# NUC122_v1 register map
File version: 1.0
Registers are 32-bit, read-write, reset 0x0 unless marked. A register's access mark holds for its fields unless they carry their own. Offsets are from the block's base; [hi:lo] are bit positions; {n}, {i} and the like mark numbered series.

## GCR — GCR Register Map
Base 0x50000000
0x00 PDID ro reset 0x140018 — Part Device Identification Number Register
  [31:0] PDID — Part Device Identification Number. This register reflects device part number code. S/W can read this register to identify which device is used.
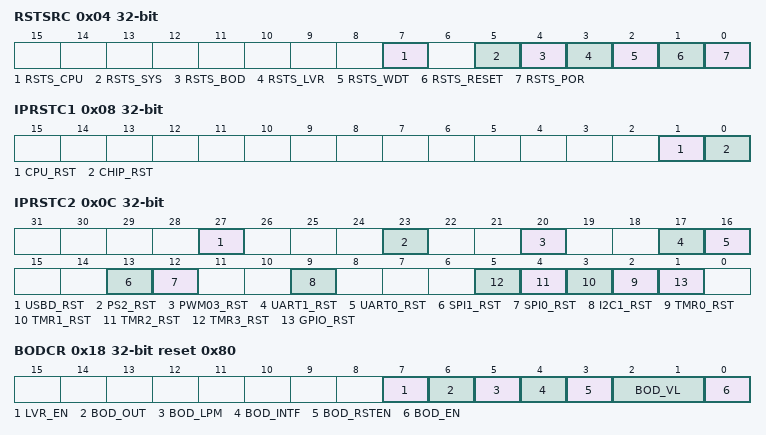
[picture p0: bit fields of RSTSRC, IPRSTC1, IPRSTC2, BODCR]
0x04 RSTSRC (reset mask 0xFFFFFF00) — System Reset Source Register
  [7] RSTS_CPU — The RSTS_CPU flag is set by hardware if software writes CPU_RST (IPRSTC1[1]) 1 to reset Cortex-M0 CPU kernel and Flash memory controller (FMC). Software can write 1 to clear this bit to zero.
    0=No reset from CPU; 1=The Cortex-M0 CPU kernel and FMC are reset by software setting CPU_RST to 1
  [5] RSTS_SYS — The RSTS_SYS flag is set by the "reset signal" from the Cortex-M0 kernel to indicate the previous reset source. Software can write 1 to clear this bit to zero.
    0=No reset from Cortex-M0; 1=The Cortex-M0 had issued the reset signal to reset the system by software writing 1 to bit SYSRESETREQ(AIRCR[2], Application Interrupt and Reset Control Register, address = 0xE000ED0C) in system control registers of Cortex-M0 kernel
  [4] RSTS_BOD — The RSTS_BOD flag is set by the "reset signal" from the Brownout Detector to indicate the previous reset source. Software can write 1 to clear this bit to zero.
    0=No reset from BOD; 1=The BOD had issued the reset signal to reset the system
  [3] RSTS_LVR — The RSTS_LVR flag is set by the "reset signal" from the Low-Voltage-Reset controller to indicate the previous reset source. Software can write 1 to clear this bit to zero.
    0=No reset from LVR; 1=The LVR controller had issued the reset signal to reset the system
  [2] RSTS_WDT — The RSTS_WDT flag is set by the "reset signal" from the Watchdog Timer to indicate the previous reset source. Software can write 1 to clear this bit to zero.
    0=No reset from Watchdog Timer; 1=The Watchdog Timer had issued the reset signal to reset the system
  [1] RSTS_RESET — The RSTS_RESET flag is set by the "reset signal" from the /RESET pin to indicate the previous reset source. Software can write 1 to clear this bit to zero.
    0=No reset from /RESET pin; 1=The Pin /RESET had issued the reset signal to reset the system
  [0] RSTS_POR — The RSTS_POR flag is set by the "reset signal" from the Power-On Reset (POR) controller or bit CHIP_RST (IPRSTC1[0]) to indicate the previous reset source. Software can write 1 to clear this bit to zero.
    0=No reset from POR or CHIP_RST; 1=The Power-On Reset (POR) or CHIP_RST had issued the reset signal to reset the system
0x08 IPRSTC1 — Peripheral Reset Control Register 1
  [1] CPU_RST — CPU Kernel One Shot Reset (write-protection bit). Setting this bit will only reset the CPU kernel and Flash Memory Controller(FMC), and this bit will automatically return to 0 after the 2 clock cycles. This bit is the protected bit, It means programming this bit needs to write "59h", "16h", "88h" to address 0x5000_0100 to disable register protection. Reference the register REGWRPROT at address GCR_BA+0x100
    0=CPU normal operation; 1=CPU one shot reset
  [0] CHIP_RST — CHIP One Shot Reset (write-protection bit). Setting this bit will reset the whole chip, including CPU kernel and all peripherals, and this bit will automatically return to 0 after the 2 clock cycles. The CHIP_RST is same as the POR reset, all the chip controllers is reset and the chip setting from flash are also reload. About the difference between CHIP_RST and SYSRESETREQ, please refer to section 5.2.2. This bit is the protected bit. It means programming this bit needs to write "59h", "16h", "88h" to address 0x5000_0100 to disable register protection. Reference the register REGWRPROT at address GCR_BA+0x100
    0=CHIP normal operation; 1=CHIP one shot reset
0x0C IPRSTC2 — Peripheral Reset Control Register 2
  [27] USBD_RST — USB Device Controller Reset
    0=USB device controller normal operation; 1=USB device controller reset
  [23] PS2_RST — PS/2 Controller Reset
    0=PS/2 controller normal operation; 1=PS/2 controller reset
  [20] PWM03_RST — PWM03 Controller Reset
    0=PWM03 controller normal operation; 1=PWM03 controller reset
  [17] UART1_RST — UART1 Controller Reset
    0=UART1 controller normal operation; 1=UART1 controller reset
  [16] UART0_RST — UART0 Controller Reset
    0=UART0 controller normal operation; 1=UART0 controller reset
  [13] SPI1_RST — SPI1 Controller Reset
    0=SPI1 controller normal operation; 1=SPI1 controller reset
  [12] SPI0_RST — SPI0 Controller Reset
    0=SPI0 controller normal operation; 1=SPI0 controller reset
  [9] I2C1_RST — I2C1 Controller Reset
    0=I2C1 controller normal operation; 1=I2C1 controller reset
  [n+2] TMR{n}_RST (n=0..3) — Timer{n} Controller Reset
    0=Timer{n} controller normal operation; 1=Timer{n} controller reset
  [1] GPIO_RST — GPIO Controller Reset
    0=GPIO controller normal operation; 1=GPIO controller reset
0x18 BODCR reset 0x80 (reset mask 0xFFFFFFF0) — Brownout Detector Control Register
  [7] LVR_EN — Low Voltage Reset Enable (write-protection bit). The LVR function reset the chip when the input power voltage is lower than LVR circuit setting. LVR function is enabled in default. This bit is the protected bit. It means programming this needs to write "59h", "16h", "88h" to address 0x5000_0100 to disable register protection. Reference the register REGWRPROT at address GCR_BA+0x100
    0=Disabled Low Voltage Reset function; 1=Enabled Low Voltage Reset function - After enabling the bit, the LVR function will be active with 100uS delay for LVR output stable. (default)
  [6] BOD_OUT — Brownout Detector Output Status
    0=Brownout Detector output status is 0. It means the detected voltage is higher than BOD_VL setting or BOD_EN is 0; 1=Brownout Detector output status is 1. It means the detected voltage is lower than BOD_VL setting. If the BOD_EN is 0, BOD function disabled , this bit always responds 0
  [5] BOD_LPM — Brownout Detector Low Power Mode (write-protection bit). The BOD consumes about 100 uA in normal mode, the low power mode can reduce the current to about 1/10 but slow the BOD response. This bit is the protected bit. It means programming this needs to write "59h", "16h", "88h" to address 0x5000_0100 to disable register protection. Reference the register REGWRPROT at address GCR_BA+0x100.
    0=BOD operate in normal mode (default); 1=Enable the BOD low power mode
  [4] BOD_INTF — Brownout Detector Interrupt Flag. Software can write 1 to clear this bit to zero.
    0=Brownout Detector does not detect any voltage draft at VDD down through or up through the voltage of BOD_VL setting; 1=When Brownout Detector detects the VDD is dropped down through the voltage of BOD_VL setting or the VDD is raised up through the voltage of BOD_VL setting, this bit is set to 1 and the brownout interrupt is requested if brownout interrupt is enabled
  [3] BOD_RSTEN — Brownout Reset Enable (write-protection bit). While the BOD function is enabled (BOD_EN high) and BOD interrupt function is enabled (BOD_RSTEN low), BOD will assert an interrupt if BOD_OUT is high. BOD interrupt will keep till to the BOD_EN set to 0. BOD interrupt can be blocked by disabling the NVIC BOD interrupt or disabling BOD function (set BOD_EN low). The default value is set by flash controller user configuration register config0 bit[20]. This bit is the protected bit. It means programming this needs to write "59h", "16h", "88h" to address 0x5000_0100 to disable register protection. Reference the register REGWRPROT at address GCR_BA+0x100.
    0=Enable the brownout "INTERRUPT" function; 1=Enable the brownout "RESET" function
  [2:1] BOD_VL — Brownout Detector Threshold Voltage Selection (write-protection bits)
  [0] BOD_EN — Brownout Detector Enable (write-protection bit). The default value is set by flash controller user configuration register config0 bit[23]. This bit is the protected bit. It means programming this needs to write "59h", "16h", "88h" to address 0x5000_0100 to disable register protection. Reference the register REGWRPROT at address GCR_BA+0x100.
    0=Brownout Detector function is disabled; 1=Brownout Detector function is enabled
0x24 PORCR (reset mask 0xFFFFFF00) — Power-On Reset Control Register
  [15:0] POR_DIS_CODE — The register is used for the Power-On Reset enable control (write-protection bits). When power on, the POR circuit generates a reset signal to reset the whole chip function, but noise on the power may cause the POR active again. User can disable internal POR circuit to avoid unpredictable noise to cause chip reset by writing 0x5AA5 to this field. The POR function will be active again when this field is set to another value or chip is reset by other reset source, including: /RESET pin, Watchdog Timer Time-Out reset, LVR reset, BOD reset, ICE reset command and the software-chip reset function. This bit is the protected bit. It means programming this needs to write "59h", "16h", "88h" to address 0x5000_0100 to disable register protection. Reference the register REGWRPROT at address GCR_BA+0x100.
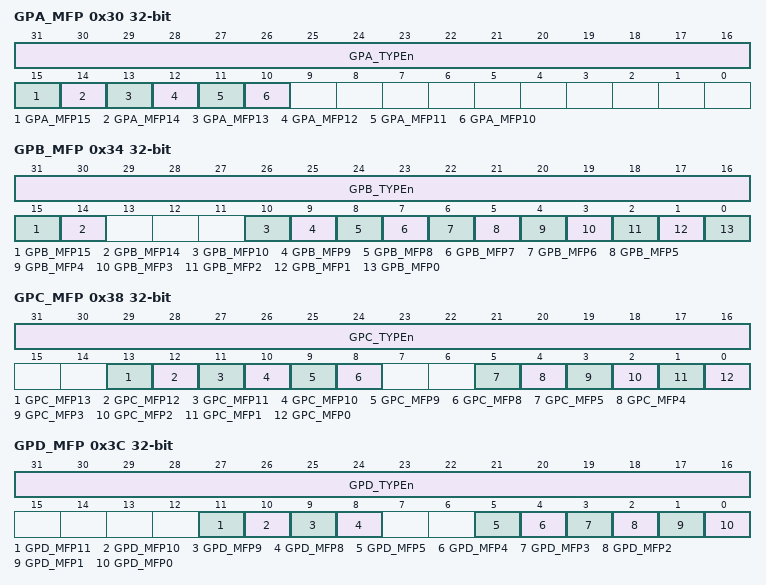
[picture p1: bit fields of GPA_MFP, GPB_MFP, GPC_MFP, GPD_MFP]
0x30 GPA_MFP — GPIOA Multiple Function and Input Type Control Register
  [31:16] GPA_TYPEn — GPA[9:0] are reserved
    0=Disable GPIOA[15:0] I/O input Schmitt Trigger function; 1=Enable GPIOA[15:0] I/O input Schmitt Trigger function
  [15] GPA_MFP15 — PA.15 Pin Function Selection
  [14] GPA_MFP14 — PA.14 Pin Function Selection
  [13] GPA_MFP13 — PA.13 Pin Function Selection
  [12] GPA_MFP12 — PA.12 Pin Function Selection
  [11] GPA_MFP11 — PA.11 Pin Function Selection
  [10] GPA_MFP10 — PA.10 Pin Function Selection
0x34 GPB_MFP — GPIOB Multiple Function and Input Type Control Register
  [31:16] GPB_TYPEn — GPB[13:11],are reserved
    0=Disable GPIOB[15:0] I/O input Schmitt Trigger function; 1=Enable GPIOB[15:0] I/O input Schmitt Trigger function
  [15] GPB_MFP15 — PB.15 Pin Function Selection
  [14] GPB_MFP14 — PB.14 Pin Function Selection
  [10] GPB_MFP10 — PB.10 Pin Function Selection
  [9] GPB_MFP9 — PB.9 Pin Function Selection
  [8] GPB_MFP8 — PB.8 Pin Function Selection
  [7] GPB_MFP7 — PB.7 Pin Function Selection
  [6] GPB_MFP6 — PB.6 Pin Function Selection
  [5] GPB_MFP5 — PB. 5 Pin Function Selection
    0=The GPIOB[5] is selected to the pin PB.5; 1=The UART1 TXD function is selected to the pin PB.5
  [4] GPB_MFP4 — PB.4 Pin Function Selection
    0=The GPIOB[4] is selected to the pin PB.4; 1=The UART1 RXD function is selected to the pin PB.4
  [3] GPB_MFP3 — PB.3 Pin Function Selection
  [2] GPB_MFP2 — PB.2 Pin Function Selection
  [1] GPB_MFP1 — PB.1 Pin Function Selection
    0=The GPIOB[1] is selected to the pin PB.1; 1=The UART0 TXD function is selected to the pin PB.1
  [0] GPB_MFP0 — PB.0 Pin Function Selection
    0=The GPIOB[0] is selected to the pin PB.0; 1=The UART0 RXD function is selected to the pin PB.0
0x38 GPC_MFP — GPIOC Multiple Function and Input Type Control Register
  [31:16] GPC_TYPEn — GPC[15:14], GPC[7:6] are reserved
    0=Disable GPIOC[15:0] I/O input Schmitt Trigger function; 1=Enable GPIOC[15:0] I/O input Schmitt Trigger function
  [13] GPC_MFP13 — PC.13 Pin Function Selection. Both GPC_MFP[13] and ALT_MFP[21] are needed to set 0 for GPIOC[13] function on PC.13.
  [12] GPC_MFP12 — PC.12 Pin Function Selection. Both GPC_MFP[12] and ALT_MFP[13] are needed to set 0 for GPIOC[12] function on PC.12.
  [11] GPC_MFP11 — PC.11 Pin Function Selection
  [10] GPC_MFP10 — PC.10 Pin Function Selection
  [9] GPC_MFP9 — PC.9 Pin Function Selection
  [8] GPC_MFP8 — PC.8 Pin Function Selection
  [5] GPC_MFP5 — PC.5 Pin Function Selection. GPC_MFP[5] is needed to set 0 for GPIOC[5] function on PC.5.
  [4] GPC_MFP4 — PC.4 Pin Function Selection. GPC_MFP[4] is needed to set 0 for GPIOC[4] function on PC.4.
  [3] GPC_MFP3 — PC.3 Pin Function Selection
  [2] GPC_MFP2 — PC.2 Pin Function Selection
  [1] GPC_MFP1 — PC.1 Pin Function Selection
  [0] GPC_MFP0 — PC.0 Pin Function Selection
0x3C GPD_MFP — GPIOD Multiple Function and Input Type Control Register
  [31:16] GPD_TYPEn — GPIOD[15:12], GPIOD[7:6] are reserved
    0=Disable GPIOD[15:0] I/O input Schmitt Trigger function; 1=Enable GPIOD[15:0] I/O input Schmitt Trigger function
  [11] GPD_MFP11 — PD.11 Pin Function Selection. Both GPD_MFP[11] and ALT_MFP[21] are needed to set 0 for GPIOD[11] function on PD.11
  [10] GPD_MFP10 — PD.10 Pin Function Selection. Both GPD_MFP[10] and ALT_MFP[20] are needed to set 0 for GPIOD[10] function on PD.10
  [9] GPD_MFP9 — PD.9 Pin Function Selection. Both GPD_MFP[9] and ALT_MFP[19] are needed to set 0 for GPIOD[9] function on PD.9
  [8] GPD_MFP8 — PD.8 Pin Function Selection. Both GPD_MFP[8] and ALT_MFP[18] are needed to set 0 for GPIOD[8] function on PD.8
  [5] GPD_MFP5 — PD.5 Pin Function Selection. GPD_MFP[5] is needed to set 0 for GPIOD[5] function on PD.5
  [4] GPD_MFP4 — PD.4 Pin Function Selection. GPD_MFP[4] is needed to set 0 for GPIOD[4] function on PD.4
  [3] GPD_MFP3 — PD.3 Pin Function Selection. GPD_MFP[3] is needed to set 0 for GPIOD[3] function on PD.3
  [2] GPD_MFP2 — PD.2 Pin Function Selection. GPD_MFP[2] is needed to set 0 for GPIOD[2] function on PD.2
  [1] GPD_MFP1 — PD.1 Pin Function Selection
    0=The GPIOD[1] is selected to the pin PD.1; 1=The SPI0 SS01 function is selected to the pin PD.1(the validity of this function is depended on part no)
  [0] GPD_MFP0 — PD.0 Pin Function Selection. GPD_MFP[0] is needed to set 0 for GPIOD[0] function on PD.0
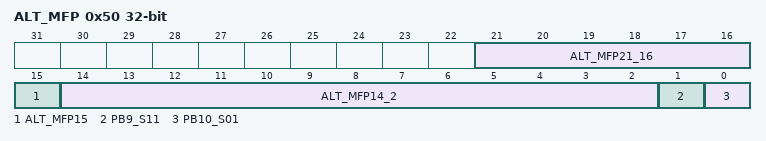
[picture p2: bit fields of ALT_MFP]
0x50 ALT_MFP — Alternative Multiple Function Pin Control Register
  [21:16] ALT_MFP21_16 — They are necessary to set 0
  [15] ALT_MFP15 — The PB.4 pin function depends on GPB_MFP4 and ALT_MFP[15].
  [14:2] ALT_MFP14_2 — They are necessary to set 0
  [1] PB9_S11 — Bits PB9_S11 and GPB_MFP[9] determine the PB.9 function.
  [0] PB10_S01 — Bits PB10_S01 and GPB_MFP[10] determine the PB.10 function.
0x100 REGWRPROT — Register Write-Protection Control Register
  [0] REGPROTDIS ro — Register Write-Protection Disable Index (Read only). The Protected registers are: IPRSTC1: address 0x5000_0008. BODCR: address 0x5000_0018. PORCR: address 0x5000_0024. PWRCON: address 0x5000_0200 (bit[6] is not protected for power wake-up interrupt clear). APBCLK bit[0]: address 0x5000_0208 (bit[0] is Watchdog Timer clock enable). CLK_SEL0: address 0x5000_0210 (for HCLK and CPU STCLK clock source select). CLK_SEL1 bit[1:0]: address 0x5000_0214 (for Watchdog Timer clock source select). NMI_SEL bit[7]: address 0x5000_0380 (for interrupt test mode). ISPCON: address 0x5000_C000 (Flash ISP Control register). WTCR: address 0x4000_4000. FATCON: address 0x5000_C018
    0=Write-protection is enabled for writing protected registers. Any write to the protected register is ignored; 1=Write-protection is disabled for writing protected registers
  [7:0] REGWRPROT wo — Register Write-Protection Code (Write only). Some registers have write-protection function. Writing these registers have to disable the protected function by writing the sequence value "59h", "16h", "88h" to this field. After this sequence is completed, the REGPROTDIS bit will be set to 1 and write-protection registers can be normal write.
